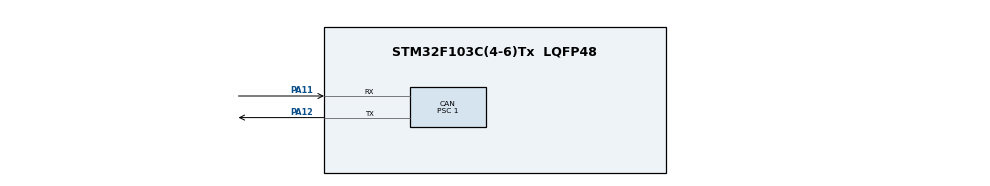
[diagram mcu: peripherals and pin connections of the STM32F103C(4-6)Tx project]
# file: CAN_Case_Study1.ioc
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CAN.BS1=CAN_BS1_6TQ
CAN.CalculateTimeBit=1000
CAN.CalculateTimeQuantum=125.0
CAN.Mode=CAN_MODE_LOOPBACK
CAN.Prescaler=1
Mcu.Family=STM32F1
Mcu.Name=STM32F103C(4-6)Tx
Mcu.Package=LQFP48
NVIC.PriorityGroup=NVIC_PRIORITYGROUP_4
PA11.Mode=Master
PA11.Signal=CAN_RX
PA12.Mode=Master
PA12.Signal=CAN_TX
ProjectManager.HeapSize=0x200
ProjectManager.StackSize=0x400
ProjectManager.TargetToolchain=STM32CubeIDE
RCC.APB1Freq_Value=8000000
RCC.APB2Freq_Value=8000000
VP_SYS_VS_ND.Mode=No_Debug
board=custom

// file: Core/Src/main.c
/* USER CODE BEGIN Header */
/**
  ******************************************************************************
  * @file           : main.c
  * @brief          : Main program body
  ******************************************************************************
  * @attention
  *
  * <h2><center>&copy; Copyright (c) 2023 STMicroelectronics.
  * All rights reserved.</center></h2>
  *
  * This software component is licensed by ST under BSD 3-Clause license,
  * the "License"; You may not use this file except in compliance with the
  * License. You may obtain a copy of the License at:
  *                        opensource.org/licenses/BSD-3-Clause
  *
  ******************************************************************************
  */
/* USER CODE END Header */
#include "main.h"

CAN_HandleTypeDef hcan;

void SystemClock_Config(void);
static void MX_GPIO_Init(void);
static void MX_CAN_Init(void);
/* USER CODE BEGIN PFP */
void CAN_TX(uint32_t ID , uint8_t DLC , uint8_t *PAYLOAD);
void CAN_RX(uint32_t *ID_ptr , uint8_t *DLC_ptr , uint8_t *PAYLOAD_ptr);
void CAN_Filter(uint16_t Filter_ID,uint16_t Filter_MASK);

/* USER CODE END PFP */

/* USER CODE BEGIN 0 */
void CAN_TX(uint32_t ID , uint8_t DLC , uint8_t *PAYLOAD){

	CAN_TxHeaderTypeDef TX_Header={
			.DLC=DLC,
			.IDE=CAN_ID_STD,
			.RTR=CAN_RTR_DATA,
			.StdId=ID
	};
	uint32_t MailBox;

	if(HAL_CAN_GetTxMailboxesFreeLevel(&hcan)){
		HAL_CAN_AddTxMessage(&hcan, &TX_Header, PAYLOAD, &MailBox);
		while(HAL_CAN_IsTxMessagePending(&hcan, MailBox));
	}

}
void CAN_Filter(uint16_t Filter_ID, uint16_t Filter_MASK){
	CAN_FilterTypeDef Filter_Config={
			.FilterActivation=CAN_FILTER_ENABLE,
			.FilterBank=0,
			.FilterFIFOAssignment=CAN_FILTER_FIFO0,
			.FilterIdHigh = Filter_ID<<5,
			.FilterIdLow=0,
			.FilterMaskIdHigh =Filter_MASK<<5,
			.FilterMaskIdLow =0,
			.FilterMode =CAN_FILTERMODE_IDMASK,
			.FilterScale = CAN_FILTERSCALE_32BIT
	};

	HAL_CAN_ConfigFilter(&hcan, &Filter_Config);
}

void CAN_RX(uint32_t *ID_ptr , uint8_t *DLC_ptr , uint8_t *PAYLOAD_ptr){
	CAN_RxHeaderTypeDef RX_Header;
	while(!HAL_CAN_GetRxFifoFillLevel(&hcan, 0));
	HAL_CAN_GetRxMessage(&hcan, 0, &RX_Header, PAYLOAD_ptr);
}
/* USER CODE END 0 */

int main(void)
{
  /* USER CODE BEGIN 1 */
	uint8_t Tx_Data[8] = {"CAN No: "};
	uint8_t frameNo = 0;

  /* USER CODE END 1 */

  /* MCU Configuration--------------------------------------------------------*/

  /* Reset of all peripherals, Initializes the Flash interface and the Systick. */
  HAL_Init();

  /* Configure the system clock */
  SystemClock_Config();

  /* Initialize all configured peripherals */
  MX_GPIO_Init();
  MX_CAN_Init();
  /* USER CODE BEGIN 2 */
	HAL_CAN_Start(&hcan);
	CAN_Filter(0x3FF,0x7FF);
	uint32_t ID_RX ,DLC_RX,PAYLOAD_RX;
	uint8_t i=0;
	//Tx_Data[7]=i;
  /* USER CODE END 2 */

  /* Infinite loop */
  while (1)
  {
	  Tx_Data[7]=i++;
	  CAN_TX(0x3FF, 8, Tx_Data);
	  CAN_RX(&ID_RX, &DLC_RX, &PAYLOAD_RX);

  }
}

void SystemClock_Config(void)
{
  RCC_OscInitTypeDef RCC_OscInitStruct = {0};
  RCC_ClkInitTypeDef RCC_ClkInitStruct = {0};

  /** Initializes the RCC Oscillators according to the specified parameters
  * in the RCC_OscInitTypeDef structure.
  */
  RCC_OscInitStruct.OscillatorType = RCC_OSCILLATORTYPE_HSI;
  RCC_OscInitStruct.HSIState = RCC_HSI_ON;
  RCC_OscInitStruct.HSICalibrationValue = RCC_HSICALIBRATION_DEFAULT;
  RCC_OscInitStruct.PLL.PLLState = RCC_PLL_NONE;
  if (HAL_RCC_OscConfig(&RCC_OscInitStruct) != HAL_OK)
  {
    Error_Handler();
  }
  /** Initializes the CPU, AHB and APB buses clocks
  */
  RCC_ClkInitStruct.ClockType = RCC_CLOCKTYPE_HCLK|RCC_CLOCKTYPE_SYSCLK
                              |RCC_CLOCKTYPE_PCLK1|RCC_CLOCKTYPE_PCLK2;
  RCC_ClkInitStruct.SYSCLKSource = RCC_SYSCLKSOURCE_HSI;
  RCC_ClkInitStruct.AHBCLKDivider = RCC_SYSCLK_DIV1;
  RCC_ClkInitStruct.APB1CLKDivider = RCC_HCLK_DIV1;
  RCC_ClkInitStruct.APB2CLKDivider = RCC_HCLK_DIV1;

  if (HAL_RCC_ClockConfig(&RCC_ClkInitStruct, FLASH_LATENCY_0) != HAL_OK)
  {
    Error_Handler();
  }
}

static void MX_CAN_Init(void)
{

  hcan.Instance = CAN1;
  hcan.Init.Prescaler = 1;
  hcan.Init.Mode = CAN_MODE_LOOPBACK;
  hcan.Init.SyncJumpWidth = CAN_SJW_1TQ;
  hcan.Init.TimeSeg1 = CAN_BS1_6TQ;
  hcan.Init.TimeSeg2 = CAN_BS2_1TQ;
  hcan.Init.TimeTriggeredMode = DISABLE;
  hcan.Init.AutoBusOff = DISABLE;
  hcan.Init.AutoWakeUp = DISABLE;
  hcan.Init.AutoRetransmission = DISABLE;
  hcan.Init.ReceiveFifoLocked = DISABLE;
  hcan.Init.TransmitFifoPriority = DISABLE;
  if (HAL_CAN_Init(&hcan) != HAL_OK)
  {
    Error_Handler();
  }

}

static void MX_GPIO_Init(void)
{

  /* GPIO Ports Clock Enable */
  __HAL_RCC_GPIOA_CLK_ENABLE();

}

void Error_Handler(void)
{
}

/************************ (C) COPYRIGHT STMicroelectronics *****END OF FILE****/
